# icache_secure register map
Vendor: Texas Instruments
Peripheral module from a debugger description file (folder CC35X1E).
Registers are 32-bit, access per field, reset values left out (the file's numbers can be read two ways) unless marked. A register's access mark holds for its fields unless they carry their own. Offsets are as the file gives them; lines under a group give offsets from that group; [hi:lo] are bit positions; {n}, {i} and the like mark numbered series; 'fields as' and 'values as' point back to an identical list; <NAME> marks a mode.

## icache_secure
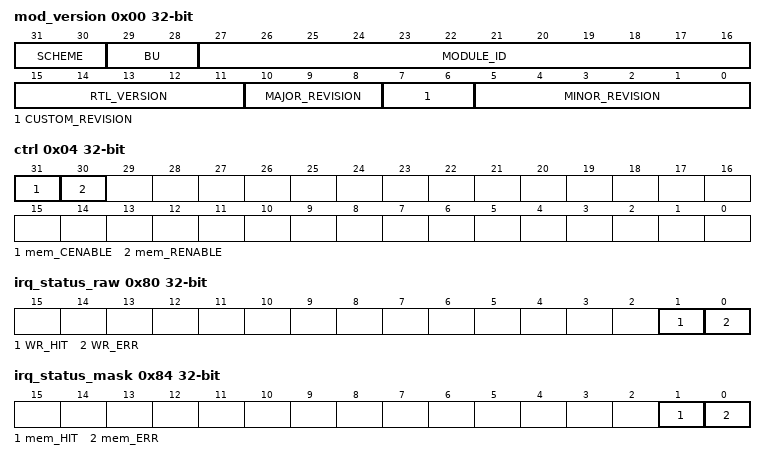
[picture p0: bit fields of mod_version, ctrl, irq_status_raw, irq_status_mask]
0x00 mod_version ro — The Module and Version Register identifies the module identifier and revision of the icache module.
  [31:30] SCHEME — Module Scheme
  [29:28] BU — Module Business Unit
  [27:16] MODULE_ID
  [15:11] RTL_VERSION
  [10:8] MAJOR_REVISION
  [7:6] CUSTOM_REVISION
  [5:0] MINOR_REVISION
0x04 ctrl — The control register defines the size of the remote cache data storage memory to use and whether the icache controller is enabled.
  [31] mem_CENABLE rw, [30] mem_RENABLE rw
0x08 status ro — The Status register displays the state of the icache controller.
  [31] OK_TO_GO — The ok_to_go status bit indicates the Tag/LRU Ram has been initialized and the cache is in an operable state.
0x10 cache_address_low — The Cache Address Low Register defines start of the cacheable space. The icache controller can cache up to a range of 8MB of of the target Flash as defined by CAL gt= CachedRange lt= CAH. This register is write protected when cenable is set.
  [31:12] mem_addr_low rw — The addr_lo defines the cache low address[31:12] for the icache controller to cache. The remaining bits 10:0 are assumed to be zero
0x18 cache_address_high — The L1 Cache Address High Register defines end of the L1 cacheable space. The L1 cache can cache up to a range of 8MB of of the target Flash as defined by CAL >= CachedRange <= CAH. This register is write protected when cenable is set.
  [31:12] mem_addr_high rw — The addr_hi defines the L1 high address[31:12] for the L1 to cache. The remaining bits 10:0 are assumed to be ones.
0x20 register_address — The RAM Address register defines the upper 17 bits of address for the RAM when renable is set. This register is write protected when renable is set
  [31:15] mem_seg_addr rw — The seg_addr defines RAM address[31:15] value for RAM access .
0x40 hit_counter rw — The HIT Counter register holds the number of cache Hits to the internal cache
  [31:0] mem_hit_counter — The hit Counts the number of hits to the L1 cache. Writing zero to this register will clear its contents.
0x44 miss_counter rw — The MISS Counter register holds the number of cache misses to the internal cache .
  [31:0] mem_miss_counter — The miss Counts the number of misses to the L1 cache. Writing zero to this register will clear its contents.
0x80 irq_status_raw — The Interrupt Raw Status Register holds the raw status of the icache error interrupts .
  [1] WR_HIT rw — The wr_hit bit indicates a write to the cacheable range has occured potentially causing a coherency issue and the L1 is logically disabled while this bit is a '1'. Write 1 to set the wr_hit status for diagnostic purposes. Writing a 0 has no effect.
  [0] WR_ERR rw — The wr_err bit indicates a write error has occured to the remote cache data storage memory and the L1 is logically disabled while this bit is a '1'. Write 1 to set the wr_err status for diagnostic purposes. Writing a 0 has no effect.
0x84 irq_status_mask — The Interrupt Masked Status Register holds the masked status for the icache error interrupts. Writing to this register will EOI the interrupt, that is if another interrupt is pending, a new pulse interrupt will be generated .
  [1] mem_HIT rw — The wr_hit bit indicates a write to the cacheable range has occured potentially causing a coherency issue and the L1 is logically disabled while this bit is a '1'. Write 1 to clear the wr_hit status after interrupt has been serviced (raw status gets cleared, i.e. even if not enabled). Writing a 0 has no effect to this field.
  [0] mem_ERR rw — The wr_err bit indicates a write error has occured to the remote cache data storage memory and the L1 is logically disabled while this bit is a '1'. Write 1 to clear the wr_err status after interrupt has been serviced (raw status gets cleared, i.e. even if not enabled). Writing a 0 has no effect to this field.
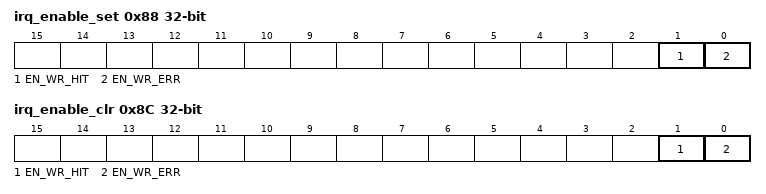
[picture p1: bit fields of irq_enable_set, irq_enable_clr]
0x88 irq_enable_set — The Interrupt Enable Set Register holds the interrupt enable status of the icache error interrupts .
  [1] EN_WR_HIT rw — Interrupt Enable Set for wr_hit error bit. Writing a 1 will enable the interrupt, and set this bit as well as the corresponding Interrupt Enable Clear Register. Writing a 0 has no effect.
  [0] EN_WR_ERR rw — Interrupt Enable Set for wr_err error bit. Writing a 1 will enable the interrupt, and set this bit as well as the corresponding Interrupt Enable Clear Register. Writing a 0 has no effect.
0x8C irq_enable_clr — The Interrupt Enable Clear Register holds the interrupt enable status of the icache error interrupts.
  [1] EN_WR_HIT rw — Interrupt Enable Clear for wr_hit error bit. Writing a 1 will disable the interrupt, and clear this bit as well as the corresponding Interrupt Enable Set Register. Writing a 0 has no effect
  [0] EN_WR_ERR rw — Interrupt Enable Clear for wr_err error bit. Writing a 1 will disable the interrupt, and clear this bit as well as the corresponding Interrupt Enable Set Register. Writing a 0 has no effect.
